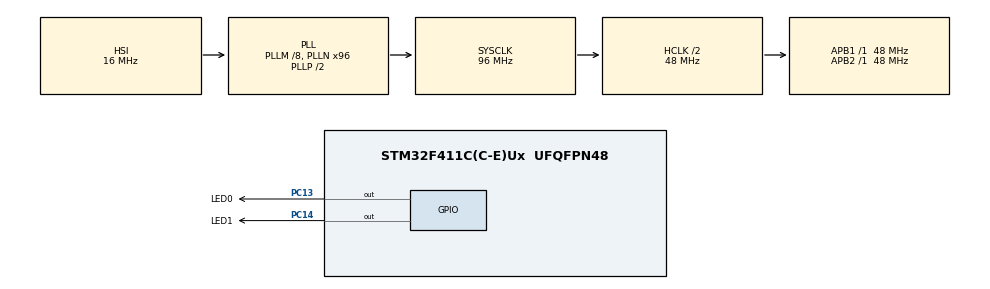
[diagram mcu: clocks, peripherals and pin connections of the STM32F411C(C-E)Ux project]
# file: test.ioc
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Mcu.Family=STM32F4
Mcu.Name=STM32F411C(C-E)Ux
Mcu.Package=UFQFPN48
NVIC.PriorityGroup=NVIC_PRIORITYGROUP_4
PA13.Mode=Serial_Wire
PA13.Signal=SYS_JTMS-SWDIO
PA14.Mode=Serial_Wire
PA14.Signal=SYS_JTCK-SWCLK
PC13-ANTI_TAMP.GPIO_Label=LED0
PC13-ANTI_TAMP.Signal=GPIO_Output
PC14-OSC32_IN.GPIO_Label=LED1
PC14-OSC32_IN.Signal=GPIO_Output
ProjectManager.HeapSize=0x200
ProjectManager.StackSize=0x400
ProjectManager.TargetToolchain=MDK-ARM V5.27
RCC.48MHZClocksFreq_Value=48000000
RCC.AHBCLKDivider=RCC_SYSCLK_DIV2
RCC.AHBFreq_Value=48000000
RCC.APB1Freq_Value=48000000
RCC.APB1TimFreq_Value=48000000
RCC.APB2Freq_Value=48000000
RCC.APB2TimFreq_Value=48000000
RCC.CortexFreq_Value=48000000
RCC.HCLKFreq_Value=48000000
RCC.HSE_VALUE=25000000
RCC.HSI_VALUE=16000000
RCC.LSE_VALUE=32768
RCC.PLLM=8
RCC.PLLN=96
RCC.SYSCLKFreq_VALUE=96000000
RCC.SYSCLKSource=RCC_SYSCLKSOURCE_PLLCLK
RCC.VCOOutputFreq_Value=192000000
board=custom

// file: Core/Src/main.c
/* USER CODE BEGIN Header */
/**
  ******************************************************************************
  * @file           : main.c
  * @brief          : Main program body
  ******************************************************************************
  * @attention
  *
  * <h2><center>&copy; Copyright (c) 2021 STMicroelectronics.
  * All rights reserved.</center></h2>
  *
  * This software component is licensed by ST under BSD 3-Clause license,
  * the "License"; You may not use this file except in compliance with the
  * License. You may obtain a copy of the License at:
  *                        opensource.org/licenses/BSD-3-Clause
  *
  ******************************************************************************
  */
/* USER CODE END Header */
#include "main.h"

/* USER CODE BEGIN PD */
#define LED_SINGLE_BLINK_TIME 100
/* USER CODE END PD */

/* USER CODE BEGIN PV */
static uint32_t time = 0;
/* USER CODE END PV */

void SystemClock_Config(void);
static void MX_GPIO_Init(void);

int main(void)
{

  /* MCU Configuration--------------------------------------------------------*/

  /* Reset of all peripherals, Initializes the Flash interface and the Systick. */
  HAL_Init();

  /* Configure the system clock */
  SystemClock_Config();

  /* Initialize all configured peripherals */
  MX_GPIO_Init();

  /* Infinite loop */
  /* USER CODE BEGIN WHILE */
  while (1)
  {
      if ((HAL_GetTick() - time) >= LED_SINGLE_BLINK_TIME)
      {
				time = HAL_GetTick();
        HAL_GPIO_TogglePin(LED0_GPIO_Port, LED0_Pin);
        HAL_GPIO_TogglePin(LED1_GPIO_Port, LED1_Pin);
      }
    /* USER CODE END WHILE */

  }
}

void SystemClock_Config(void)
{
  RCC_OscInitTypeDef RCC_OscInitStruct = {0};
  RCC_ClkInitTypeDef RCC_ClkInitStruct = {0};

  /** Configure the main internal regulator output voltage
  */
  __HAL_RCC_PWR_CLK_ENABLE();
  __HAL_PWR_VOLTAGESCALING_CONFIG(PWR_REGULATOR_VOLTAGE_SCALE1);
  /** Initializes the RCC Oscillators according to the specified parameters
  * in the RCC_OscInitTypeDef structure.
  */
  RCC_OscInitStruct.OscillatorType = RCC_OSCILLATORTYPE_HSI;
  RCC_OscInitStruct.HSIState = RCC_HSI_ON;
  RCC_OscInitStruct.HSICalibrationValue = RCC_HSICALIBRATION_DEFAULT;
  RCC_OscInitStruct.PLL.PLLState = RCC_PLL_ON;
  RCC_OscInitStruct.PLL.PLLSource = RCC_PLLSOURCE_HSI;
  RCC_OscInitStruct.PLL.PLLM = 8;
  RCC_OscInitStruct.PLL.PLLN = 96;
  RCC_OscInitStruct.PLL.PLLP = RCC_PLLP_DIV2;
  RCC_OscInitStruct.PLL.PLLQ = 4;
  if (HAL_RCC_OscConfig(&RCC_OscInitStruct) != HAL_OK)
  {
    Error_Handler();
  }
  /** Initializes the CPU, AHB and APB buses clocks
  */
  RCC_ClkInitStruct.ClockType = RCC_CLOCKTYPE_HCLK|RCC_CLOCKTYPE_SYSCLK
                              |RCC_CLOCKTYPE_PCLK1|RCC_CLOCKTYPE_PCLK2;
  RCC_ClkInitStruct.SYSCLKSource = RCC_SYSCLKSOURCE_PLLCLK;
  RCC_ClkInitStruct.AHBCLKDivider = RCC_SYSCLK_DIV2;
  RCC_ClkInitStruct.APB1CLKDivider = RCC_HCLK_DIV1;
  RCC_ClkInitStruct.APB2CLKDivider = RCC_HCLK_DIV1;

  if (HAL_RCC_ClockConfig(&RCC_ClkInitStruct, FLASH_LATENCY_1) != HAL_OK)
  {
    Error_Handler();
  }
}

static void MX_GPIO_Init(void)
{
  GPIO_InitTypeDef GPIO_InitStruct = {0};

  /* GPIO Ports Clock Enable */
  __HAL_RCC_GPIOC_CLK_ENABLE();
  __HAL_RCC_GPIOA_CLK_ENABLE();

  /*Configure GPIO pin Output Level */
  HAL_GPIO_WritePin(GPIOC, LED0_Pin|LED1_Pin, GPIO_PIN_RESET);

  /*Configure GPIO pins : LED0_Pin LED1_Pin */
  GPIO_InitStruct.Pin = LED0_Pin|LED1_Pin;
  GPIO_InitStruct.Mode = GPIO_MODE_OUTPUT_PP;
  GPIO_InitStruct.Pull = GPIO_NOPULL;
  GPIO_InitStruct.Speed = GPIO_SPEED_FREQ_LOW;
  HAL_GPIO_Init(GPIOC, &GPIO_InitStruct);

}

void Error_Handler(void)
{
  __disable_irq();
  while (1)
  {
  }
}

/************************ (C) COPYRIGHT STMicroelectronics *****END OF FILE****/
